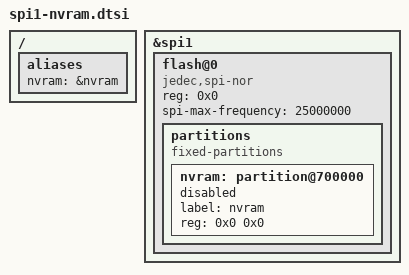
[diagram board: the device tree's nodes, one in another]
// SPDX-License-Identifier: GPL-2.0+ OR MIT
//
// Devicetree include for common spi-nor nvram flash.
//
// Apple uses a consistent configiguration for the nvram on all known M1* and
// M2* devices.
//
// Copyright The Asahi Linux Contributors

/ {
	aliases {
		nvram = &nvram;
	};
};

&spi1 {
	status = "okay";

	flash@0 {
		compatible = "jedec,spi-nor";
		reg = <0x0>;
		spi-max-frequency = <25000000>;

		partitions {
			compatible = "fixed-partitions";
			#address-cells = <1>;
			#size-cells = <1>;

			nvram: partition@700000 {
				label = "nvram";
				/* To be filled by the loader */
				reg = <0x0 0x0>;
				status = "disabled";
			};
		};
	};
};
